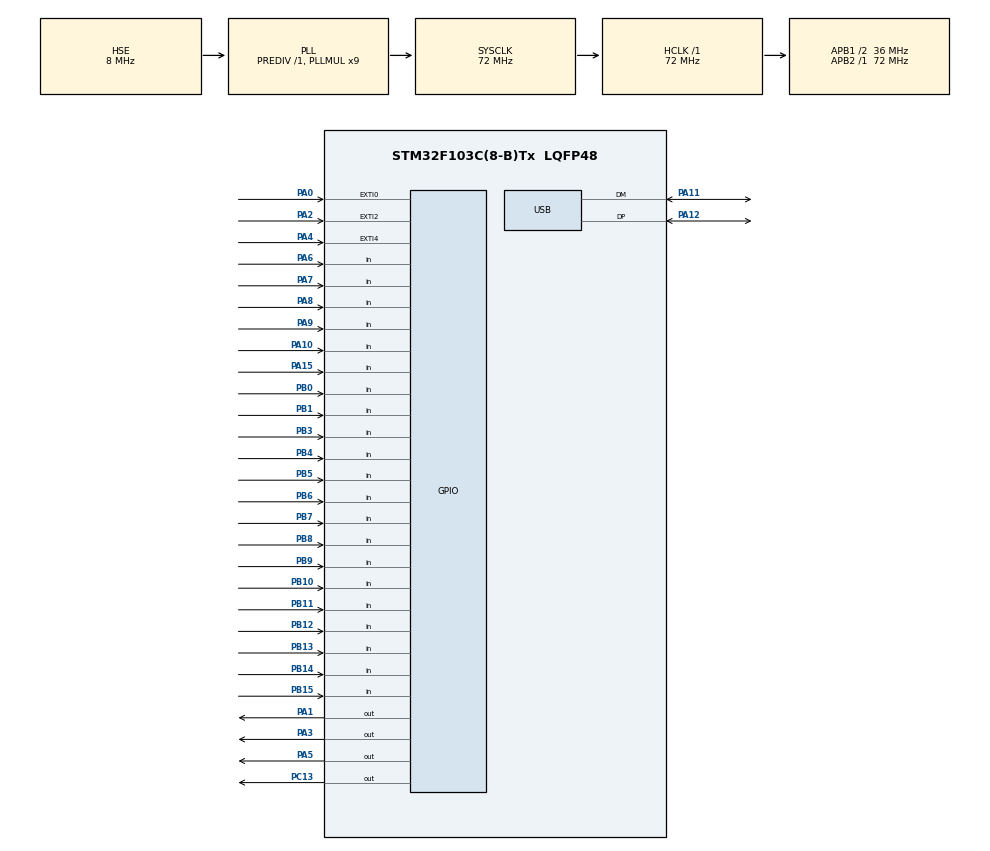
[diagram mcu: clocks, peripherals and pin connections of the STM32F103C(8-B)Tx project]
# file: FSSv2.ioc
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Mcu.Family=STM32F1
Mcu.Name=STM32F103C(8-B)Tx
Mcu.Package=LQFP48
NVIC.EXTI0_IRQn=true\:1\:0\:true\:false\:true\:true\:true\:true
NVIC.EXTI2_IRQn=true\:1\:0\:true\:false\:true\:true\:true\:true
NVIC.EXTI4_IRQn=true\:1\:0\:true\:false\:true\:true\:true\:true
NVIC.PriorityGroup=NVIC_PRIORITYGROUP_4
NVIC.USB_LP_CAN1_RX0_IRQn=true\:0\:0\:true\:false\:true\:true\:true\:true
PA0-WKUP.GPIO_ModeDefaultEXTI=GPIO_MODE_IT_FALLING
PA0-WKUP.GPIO_PuPd=GPIO_PULLUP
PA0-WKUP.Signal=GPXTI0
PA1.GPIO_PuPd=GPIO_PULLDOWN
PA1.Signal=GPIO_Output
PA10.GPIO_PuPd=GPIO_PULLUP
PA10.Signal=GPIO_Input
PA11.Mode=Device
PA11.Signal=USB_DM
PA12.Mode=Device
PA12.Signal=USB_DP
PA13.Mode=Serial_Wire
PA13.Signal=SYS_JTMS-SWDIO
PA14.Mode=Serial_Wire
PA14.Signal=SYS_JTCK-SWCLK
PA15.GPIO_PuPd=GPIO_PULLUP
PA15.Signal=GPIO_Input
PA2.GPIO_ModeDefaultEXTI=GPIO_MODE_IT_FALLING
PA2.GPIO_PuPd=GPIO_PULLUP
PA2.Signal=GPXTI2
PA3.GPIO_PuPd=GPIO_PULLDOWN
PA3.Signal=GPIO_Output
PA4.GPIO_ModeDefaultEXTI=GPIO_MODE_IT_FALLING
PA4.GPIO_PuPd=GPIO_PULLUP
PA4.Signal=GPXTI4
PA5.GPIO_PuPd=GPIO_PULLDOWN
PA5.Signal=GPIO_Output
PA6.GPIO_PuPd=GPIO_PULLUP
PA6.Signal=GPIO_Input
PA7.GPIO_PuPd=GPIO_PULLUP
PA7.Signal=GPIO_Input
PA8.GPIO_PuPd=GPIO_PULLUP
PA8.Signal=GPIO_Input
PA9.GPIO_PuPd=GPIO_PULLUP
PA9.Signal=GPIO_Input
PB0.GPIO_PuPd=GPIO_PULLUP
PB0.Signal=GPIO_Input
PB1.GPIO_PuPd=GPIO_PULLUP
PB1.Signal=GPIO_Input
PB10.GPIO_PuPd=GPIO_PULLUP
PB10.Signal=GPIO_Input
PB11.GPIO_PuPd=GPIO_PULLUP
PB11.Signal=GPIO_Input
PB12.GPIO_PuPd=GPIO_PULLUP
PB12.Signal=GPIO_Input
PB13.GPIO_PuPd=GPIO_PULLUP
PB13.Signal=GPIO_Input
PB14.GPIO_PuPd=GPIO_PULLUP
PB14.Signal=GPIO_Input
PB15.GPIO_PuPd=GPIO_PULLUP
PB15.Signal=GPIO_Input
PB3.GPIO_PuPd=GPIO_PULLUP
PB3.Signal=GPIO_Input
PB4.GPIO_PuPd=GPIO_PULLUP
PB4.Signal=GPIO_Input
PB5.GPIO_PuPd=GPIO_PULLUP
PB5.Signal=GPIO_Input
PB6.GPIO_PuPd=GPIO_PULLUP
PB6.Signal=GPIO_Input
PB7.GPIO_PuPd=GPIO_PULLUP
PB7.Signal=GPIO_Input
PB8.GPIO_PuPd=GPIO_PULLUP
PB8.Signal=GPIO_Input
PB9.GPIO_PuPd=GPIO_PULLUP
PB9.Signal=GPIO_Input
PC13-TAMPER-RTC.GPIO_PuPd=GPIO_NOPULL
PC13-TAMPER-RTC.PinState=GPIO_PIN_SET
PC13-TAMPER-RTC.Signal=GPIO_Output
PD0-OSC_IN.Mode=HSE-External-Oscillator
PD0-OSC_IN.Signal=RCC_OSC_IN
PD1-OSC_OUT.Mode=HSE-External-Oscillator
PD1-OSC_OUT.Signal=RCC_OSC_OUT
ProjectManager.HeapSize=0x400
ProjectManager.StackSize=0x400
ProjectManager.TargetToolchain=STM32CubeIDE
RCC.AHBFreq_Value=72000000
RCC.APB1CLKDivider=RCC_HCLK_DIV2
RCC.APB1Freq_Value=36000000
RCC.APB1TimFreq_Value=72000000
RCC.APB2Freq_Value=72000000
RCC.APB2TimFreq_Value=72000000
RCC.HCLKFreq_Value=72000000
RCC.PLLMUL=RCC_PLL_MUL9
RCC.SYSCLKFreq_VALUE=72000000
RCC.SYSCLKSource=RCC_SYSCLKSOURCE_PLLCLK
RCC.USBFreq_Value=48000000
RCC.USBPrescaler=RCC_USBCLKSOURCE_PLL_DIV1_5
USB_DEVICE.CLASS_NAME_FS=CUSTOM_HID
USB_DEVICE.CUSTOM_HID_FS_BINTERVAL=0x1
USB_DEVICE.PID_CUSTOMHID_FS=0x5750
USB_DEVICE.USBD_CUSTOMHID_OUTREPORT_BUF_SIZE=20
USB_DEVICE.USBD_CUSTOM_HID_REPORT_DESC_SIZE=66
USB_DEVICE.VID=0x483
USB_DEVICE.VirtualMode=CustomHid
USB_DEVICE.VirtualModeFS=Custom_Hid_FS
VP_USB_DEVICE_VS_USB_DEVICE_CUSTOM_HID_FS.Mode=CUSTOM_HID_FS
board=custom

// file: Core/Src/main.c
/* USER CODE BEGIN Header */
/**
  ******************************************************************************
  * @file           : main.c
  * @brief          : Main program body
  ******************************************************************************
  * @attention
  *
  * Copyright (c) 2026 STMicroelectronics.
  * All rights reserved.
  *
  * This software is licensed under terms that can be found in the LICENSE file
  * in the root directory of this software component.
  * If no LICENSE file comes with this software, it is provided AS-IS.
  *
  ******************************************************************************
  */
/* USER CODE END Header */
#include "main.h"
#include "usb_device.h"
#include "gpio.h"

void SystemClock_Config(void);

/* USER CODE BEGIN 0 */
extern void RealMain();
void delay_init(void) {
    CoreDebug->DEMCR |= CoreDebug_DEMCR_TRCENA_Msk;
    DWT->CYCCNT = 0;
    DWT->CTRL |= DWT_CTRL_CYCCNTENA_Msk;
}

/* USER CODE END 0 */

int main(void)
{

  /* USER CODE BEGIN 1 */
	delay_init();
  /* USER CODE END 1 */

  /* MCU Configuration--------------------------------------------------------*/

  /* Reset of all peripherals, Initializes the Flash interface and the Systick. */
  HAL_Init();

  /* Configure the system clock */
  SystemClock_Config();

  /* Initialize all configured peripherals */
  MX_GPIO_Init();
  MX_USB_DEVICE_Init();
  /* USER CODE BEGIN 2 */
  RealMain();
  /* USER CODE END 2 */

  /* Infinite loop */
  while (1)
  {

  }
}

void SystemClock_Config(void)
{
  RCC_OscInitTypeDef RCC_OscInitStruct = {0};
  RCC_ClkInitTypeDef RCC_ClkInitStruct = {0};
  RCC_PeriphCLKInitTypeDef PeriphClkInit = {0};

  /** Initializes the RCC Oscillators according to the specified parameters
  * in the RCC_OscInitTypeDef structure.
  */
  RCC_OscInitStruct.OscillatorType = RCC_OSCILLATORTYPE_HSE;
  RCC_OscInitStruct.HSEState = RCC_HSE_ON;
  RCC_OscInitStruct.HSEPredivValue = RCC_HSE_PREDIV_DIV1;
  RCC_OscInitStruct.HSIState = RCC_HSI_ON;
  RCC_OscInitStruct.PLL.PLLState = RCC_PLL_ON;
  RCC_OscInitStruct.PLL.PLLSource = RCC_PLLSOURCE_HSE;
  RCC_OscInitStruct.PLL.PLLMUL = RCC_PLL_MUL9;
  if (HAL_RCC_OscConfig(&RCC_OscInitStruct) != HAL_OK)
  {
    Error_Handler();
  }

  /** Initializes the CPU, AHB and APB buses clocks
  */
  RCC_ClkInitStruct.ClockType = RCC_CLOCKTYPE_HCLK|RCC_CLOCKTYPE_SYSCLK
                              |RCC_CLOCKTYPE_PCLK1|RCC_CLOCKTYPE_PCLK2;
  RCC_ClkInitStruct.SYSCLKSource = RCC_SYSCLKSOURCE_PLLCLK;
  RCC_ClkInitStruct.AHBCLKDivider = RCC_SYSCLK_DIV1;
  RCC_ClkInitStruct.APB1CLKDivider = RCC_HCLK_DIV2;
  RCC_ClkInitStruct.APB2CLKDivider = RCC_HCLK_DIV1;

  if (HAL_RCC_ClockConfig(&RCC_ClkInitStruct, FLASH_LATENCY_2) != HAL_OK)
  {
    Error_Handler();
  }
  PeriphClkInit.PeriphClockSelection = RCC_PERIPHCLK_USB;
  PeriphClkInit.UsbClockSelection = RCC_USBCLKSOURCE_PLL_DIV1_5;
  if (HAL_RCCEx_PeriphCLKConfig(&PeriphClkInit) != HAL_OK)
  {
    Error_Handler();
  }
}

void Error_Handler(void)
{
  __disable_irq();
  while (1)
  {
  }
}
